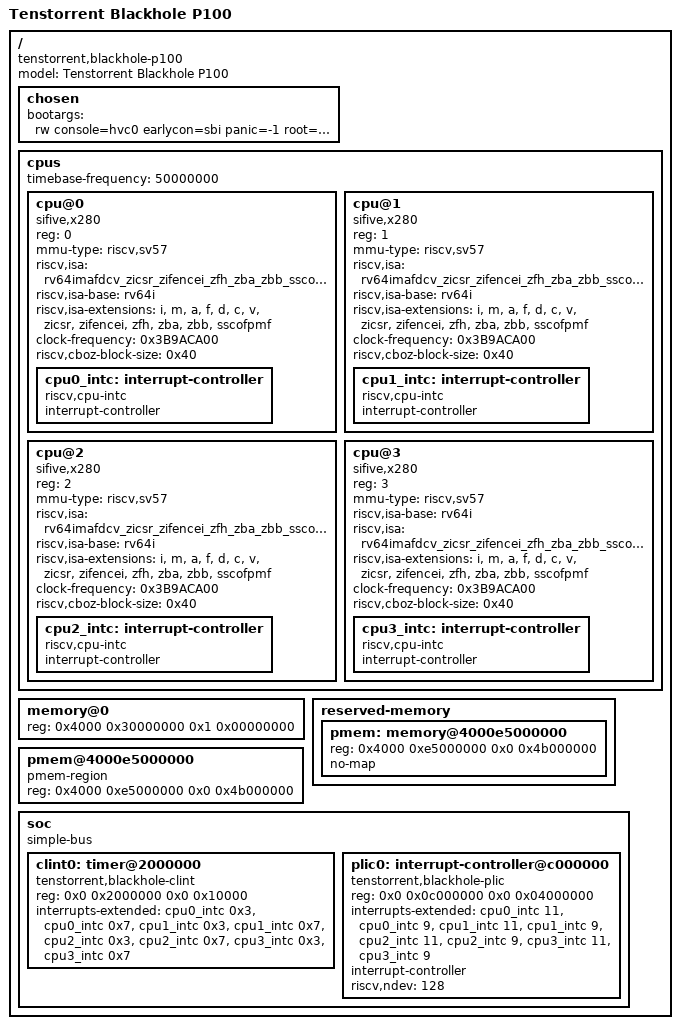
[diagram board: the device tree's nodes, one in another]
// SPDX-License-Identifier: (GPL-2.0 OR MIT)
/dts-v1/;

/ {
	model = "Tenstorrent Blackhole P100";
	compatible = "tenstorrent,blackhole-p100", "tenstorrent,blackhole";

	#address-cells = <2>;
	#size-cells = <2>;

	chosen {
		bootargs = "rw console=hvc0 earlycon=sbi panic=-1 root=/dev/pmem0";
	};

	cpus {
		#address-cells = <0x1>;
		#size-cells = <0x0>;
		timebase-frequency = <50000000>;

		cpu@0 {
			compatible = "sifive,x280", "sifive,rocket0", "riscv";
			device_type = "cpu";
			reg = <0>;
			mmu-type = "riscv,sv57";
			riscv,isa = "rv64imafdcv_zicsr_zifencei_zfh_zba_zbb_sscofpmf";
			riscv,isa-base = "rv64i";
			riscv,isa-extensions = "i", "m", "a", "f", "d", "c", "v", "zicsr",
					       "zifencei", "zfh", "zba", "zbb", "sscofpmf";
			clock-frequency = <0x3B9ACA00>;
			riscv,cboz-block-size = <0x40>;
			status = "okay";
			cpu0_intc: interrupt-controller {
				compatible = "riscv,cpu-intc";
				#interrupt-cells = <1>;
				interrupt-controller;
			};
		};

		cpu@1 {
			compatible = "sifive,x280", "sifive,rocket0", "riscv";
			device_type = "cpu";
			reg = <1>;
			mmu-type = "riscv,sv57";
			riscv,isa = "rv64imafdcv_zicsr_zifencei_zfh_zba_zbb_sscofpmf";
			riscv,isa-base = "rv64i";
			riscv,isa-extensions = "i", "m", "a", "f", "d", "c", "v", "zicsr",
					       "zifencei", "zfh", "zba", "zbb", "sscofpmf";
			clock-frequency = <0x3B9ACA00>;
			riscv,cboz-block-size = <0x40>;
			status = "okay";
			cpu1_intc: interrupt-controller {
				compatible = "riscv,cpu-intc";
				#interrupt-cells = <1>;
				interrupt-controller;
			};
		};

		cpu@2 {
			compatible = "sifive,x280", "sifive,rocket0", "riscv";
			device_type = "cpu";
			reg = <2>;
			mmu-type = "riscv,sv57";
			riscv,isa = "rv64imafdcv_zicsr_zifencei_zfh_zba_zbb_sscofpmf";
			riscv,isa-base = "rv64i";
			riscv,isa-extensions = "i", "m", "a", "f", "d", "c", "v", "zicsr",
					       "zifencei", "zfh", "zba", "zbb", "sscofpmf";
			clock-frequency = <0x3B9ACA00>;
			riscv,cboz-block-size = <0x40>;
			status = "okay";
			cpu2_intc: interrupt-controller {
				compatible = "riscv,cpu-intc";
				#interrupt-cells = <1>;
				interrupt-controller;
			};
		};

		cpu@3 {
			compatible = "sifive,x280", "sifive,rocket0", "riscv";
			device_type = "cpu";
			reg = <3>;
			mmu-type = "riscv,sv57";
			riscv,isa-base = "rv64i";
			riscv,isa = "rv64imafdcv_zicsr_zifencei_zfh_zba_zbb_sscofpmf";
			riscv,isa-extensions = "i", "m", "a", "f", "d", "c", "v", "zicsr",
					       "zifencei", "zfh", "zba", "zbb", "sscofpmf";
			clock-frequency = <0x3B9ACA00>;
			riscv,cboz-block-size = <0x40>;
			status = "okay";
			cpu3_intc: interrupt-controller {
				compatible = "riscv,cpu-intc";
				#interrupt-cells = <1>;
				interrupt-controller;
			};
		};
	};

	memory@0 {
		device_type = "memory";
		reg = <0x4000 0x30000000 0x1 0x00000000>; /* 4 GB */
	};

	reserved-memory {
		#address-cells = <2>;
		#size-cells = <2>;
		ranges;
		pmem: memory@4000e5000000 {
			reg = <0x4000 0xe5000000 0x0 0x4b000000>;
			no-map;
		};
	};

	pmem@4000e5000000 {
		compatible = "pmem-region";
		reg = <0x4000 0xe5000000 0x0 0x4b000000>; /* 1.2 GB */
	};

	soc {
		#address-cells = <2>;
		#size-cells = <2>;
		compatible = "simple-bus";
		ranges;

		clint0: timer@2000000 {
			compatible = "tenstorrent,blackhole-clint", "sifive,clint0";
			reg = <0x0 0x2000000 0x0 0x10000>;
			interrupts-extended = <&cpu0_intc 0x3>, <&cpu0_intc 0x7>,
					      <&cpu1_intc 0x3>, <&cpu1_intc 0x7>,
					      <&cpu2_intc 0x3>, <&cpu2_intc 0x7>,
					      <&cpu3_intc 0x3>, <&cpu3_intc 0x7>;
		};

		plic0: interrupt-controller@c000000 {
			compatible = "tenstorrent,blackhole-plic", "sifive,plic-1.0.0";
			reg = <0x0 0x0c000000 0x0 0x04000000>;
			interrupts-extended = <&cpu0_intc 11>, <&cpu0_intc 9>,
					      <&cpu1_intc 11>, <&cpu1_intc 9>,
					      <&cpu2_intc 11>, <&cpu2_intc 9>,
					      <&cpu3_intc 11>, <&cpu3_intc 9>;
			interrupt-controller;
			#interrupt-cells = <1>;
			#address-cells = <0>;
			riscv,ndev = <128>;
		};
	};
};
